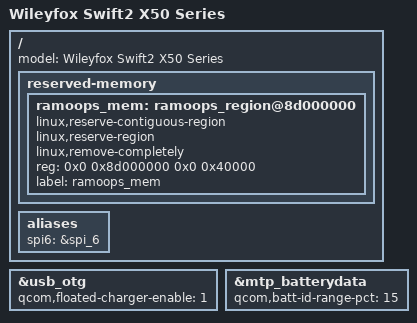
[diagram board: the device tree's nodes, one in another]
/* Copyright (c) 2020, The Linux Foundation. All rights reserved.
*  Copyright (c) 2020, Jebaitedneko.
*
* This program is free software; you can redistribute it and/or modify
* it under the terms of the GNU General Public License version 2 and
* only version 2 as published by the Free Software Foundation.
*
* This program is distributed in the hope that it will be useful,
* but WITHOUT ANY WARRANTY; without even the implied warranty of
* MERCHANTABILITY or FITNESS FOR A PARTICULAR PURPOSE.  See the
* GNU General Public License for more details.
*/

/ {
	model = "Wileyfox Swift2 X50 Series";

	reserved-memory {
		ramoops_mem: ramoops_region@8d000000 {
			  linux,reserve-contiguous-region;
			  linux,reserve-region;
			  linux,remove-completely;
			  reg = <0x0 0x8d000000 0x0 0x40000>;
			  label = "ramoops_mem";
		 };
	};
	aliases {
		 spi6 = &spi_6;
	};
};

&usb_otg {
	qcom,floated-charger-enable = <1>;
};

&mtp_batterydata {
        qcom,batt-id-range-pct = <15>;
	#include "batterydata-vk-4v35-2700mah.dtsi"
};
